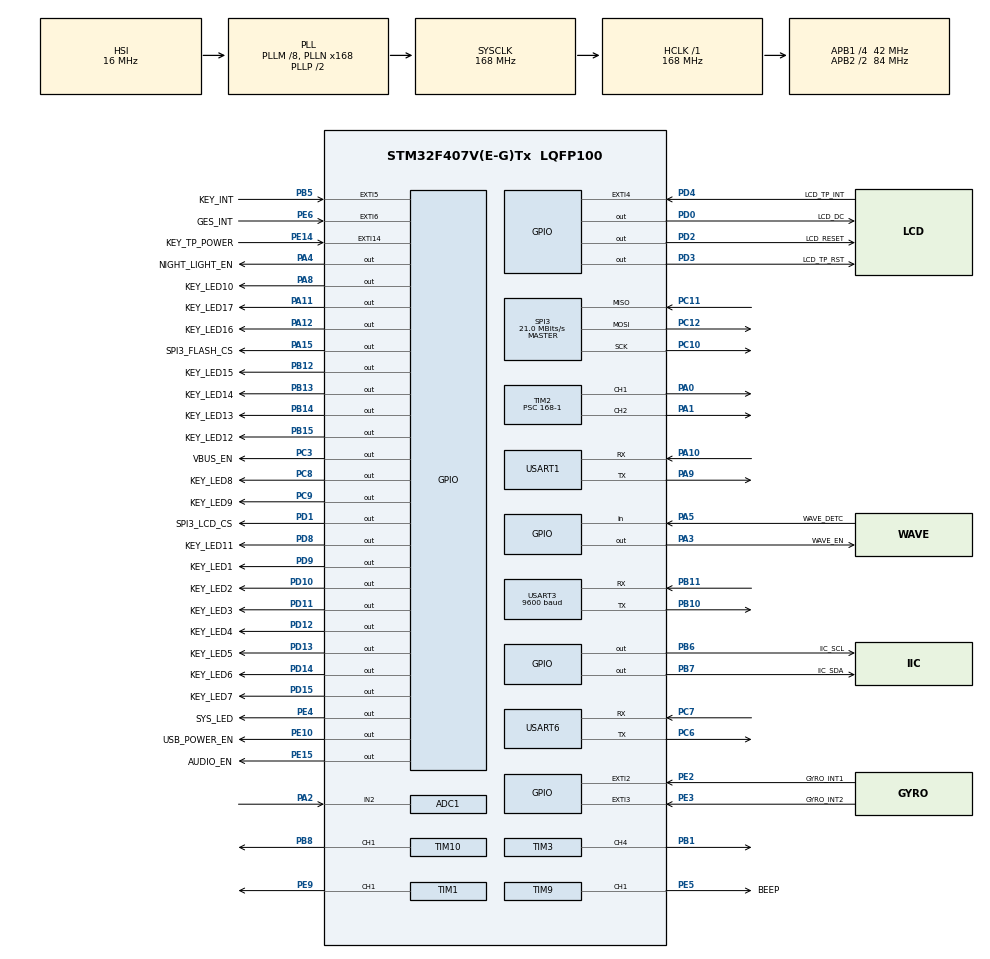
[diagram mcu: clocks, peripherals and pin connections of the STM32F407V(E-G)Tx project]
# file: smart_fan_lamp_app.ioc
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ADC1.Channel-1\#ChannelRegularConversion=ADC_CHANNEL_2
ADC1.NbrOfConversionFlag=1
ADC1.Rank-1\#ChannelRegularConversion=1
ADC1.SamplingTime-1\#ChannelRegularConversion=ADC_SAMPLETIME_3CYCLES
ADC1.master=1
Dma.Request0=USART1_RX
Dma.Request1=USART1_TX
Dma.Request2=USART6_RX
Dma.Request3=USART6_TX
Dma.Request4=USART3_RX
Dma.Request5=USART3_TX
Dma.USART1_RX.0.Direction=DMA_PERIPH_TO_MEMORY
Dma.USART1_RX.0.FIFOMode=DMA_FIFOMODE_DISABLE
Dma.USART1_RX.0.Instance=DMA2_Stream2
Dma.USART1_RX.0.MemDataAlignment=DMA_MDATAALIGN_BYTE
Dma.USART1_RX.0.MemInc=DMA_MINC_ENABLE
Dma.USART1_RX.0.Mode=DMA_NORMAL
Dma.USART1_RX.0.PeriphDataAlignment=DMA_PDATAALIGN_BYTE
Dma.USART1_RX.0.PeriphInc=DMA_PINC_DISABLE
Dma.USART1_RX.0.Priority=DMA_PRIORITY_LOW
Dma.USART1_TX.1.Direction=DMA_MEMORY_TO_PERIPH
Dma.USART1_TX.1.FIFOMode=DMA_FIFOMODE_DISABLE
Dma.USART1_TX.1.Instance=DMA2_Stream7
Dma.USART1_TX.1.MemDataAlignment=DMA_MDATAALIGN_BYTE
Dma.USART1_TX.1.MemInc=DMA_MINC_ENABLE
Dma.USART1_TX.1.Mode=DMA_NORMAL
Dma.USART1_TX.1.PeriphDataAlignment=DMA_PDATAALIGN_BYTE
Dma.USART1_TX.1.PeriphInc=DMA_PINC_DISABLE
Dma.USART1_TX.1.Priority=DMA_PRIORITY_LOW
Dma.USART3_RX.4.Direction=DMA_PERIPH_TO_MEMORY
Dma.USART3_RX.4.FIFOMode=DMA_FIFOMODE_DISABLE
Dma.USART3_RX.4.Instance=DMA1_Stream1
Dma.USART3_RX.4.MemDataAlignment=DMA_MDATAALIGN_BYTE
Dma.USART3_RX.4.MemInc=DMA_MINC_ENABLE
Dma.USART3_RX.4.Mode=DMA_NORMAL
Dma.USART3_RX.4.PeriphDataAlignment=DMA_PDATAALIGN_BYTE
Dma.USART3_RX.4.PeriphInc=DMA_PINC_DISABLE
Dma.USART3_RX.4.Priority=DMA_PRIORITY_LOW
Dma.USART3_TX.5.Direction=DMA_MEMORY_TO_PERIPH
Dma.USART3_TX.5.FIFOMode=DMA_FIFOMODE_DISABLE
Dma.USART3_TX.5.Instance=DMA1_Stream3
Dma.USART3_TX.5.MemDataAlignment=DMA_MDATAALIGN_BYTE
Dma.USART3_TX.5.MemInc=DMA_MINC_ENABLE
Dma.USART3_TX.5.Mode=DMA_NORMAL
Dma.USART3_TX.5.PeriphDataAlignment=DMA_PDATAALIGN_BYTE
Dma.USART3_TX.5.PeriphInc=DMA_PINC_DISABLE
Dma.USART3_TX.5.Priority=DMA_PRIORITY_LOW
Dma.USART6_RX.2.Direction=DMA_PERIPH_TO_MEMORY
Dma.USART6_RX.2.FIFOMode=DMA_FIFOMODE_DISABLE
Dma.USART6_RX.2.Instance=DMA2_Stream1
Dma.USART6_RX.2.MemDataAlignment=DMA_MDATAALIGN_BYTE
Dma.USART6_RX.2.MemInc=DMA_MINC_ENABLE
Dma.USART6_RX.2.Mode=DMA_NORMAL
Dma.USART6_RX.2.PeriphDataAlignment=DMA_PDATAALIGN_BYTE
Dma.USART6_RX.2.PeriphInc=DMA_PINC_DISABLE
Dma.USART6_RX.2.Priority=DMA_PRIORITY_LOW
Dma.USART6_TX.3.Direction=DMA_MEMORY_TO_PERIPH
Dma.USART6_TX.3.FIFOMode=DMA_FIFOMODE_DISABLE
Dma.USART6_TX.3.Instance=DMA2_Stream6
Dma.USART6_TX.3.MemDataAlignment=DMA_MDATAALIGN_BYTE
Dma.USART6_TX.3.MemInc=DMA_MINC_ENABLE
Dma.USART6_TX.3.Mode=DMA_NORMAL
Dma.USART6_TX.3.PeriphDataAlignment=DMA_PDATAALIGN_BYTE
Dma.USART6_TX.3.PeriphInc=DMA_PINC_DISABLE
Dma.USART6_TX.3.Priority=DMA_PRIORITY_LOW
FREERTOS.Tasks01=defaultTask,24,128,StartDefaultTask,Default,NULL,Dynamic,NULL,NULL
Mcu.Family=STM32F4
Mcu.Name=STM32F407V(E-G)Tx
Mcu.Package=LQFP100
NVIC.DMA1_Stream1_IRQn=true\:5\:0\:false\:false\:true\:true\:false\:true\:true
NVIC.DMA1_Stream3_IRQn=true\:5\:0\:false\:false\:true\:true\:false\:true\:true
NVIC.DMA2_Stream1_IRQn=true\:5\:0\:false\:false\:true\:true\:false\:true\:true
NVIC.DMA2_Stream2_IRQn=true\:5\:0\:false\:false\:true\:true\:false\:true\:true
NVIC.DMA2_Stream6_IRQn=true\:5\:0\:false\:false\:true\:true\:false\:true\:true
NVIC.DMA2_Stream7_IRQn=true\:5\:0\:false\:false\:true\:true\:false\:true\:true
NVIC.EXTI2_IRQn=true\:5\:0\:false\:false\:true\:true\:true\:true\:true
NVIC.EXTI3_IRQn=true\:5\:0\:false\:false\:true\:true\:true\:true\:true
NVIC.EXTI4_IRQn=true\:5\:0\:false\:false\:true\:true\:true\:true\:true
NVIC.EXTI9_5_IRQn=true\:5\:0\:false\:false\:true\:true\:true\:true\:true
NVIC.PriorityGroup=NVIC_PRIORITYGROUP_4
NVIC.TIM7_IRQn=true\:0\:0\:true\:false\:true\:false\:false\:true\:true
NVIC.TimeBase=TIM7_IRQn
NVIC.TimeBaseIP=TIM7
NVIC.USART1_IRQn=true\:5\:0\:false\:false\:true\:true\:false\:true\:true
NVIC.USART3_IRQn=true\:5\:0\:false\:false\:true\:true\:true\:true\:true
NVIC.USART6_IRQn=true\:5\:0\:false\:false\:true\:true\:true\:true\:true
PA0-WKUP.Signal=S_TIM2_CH1_ETR
PA1.Signal=S_TIM2_CH2
PA10.Mode=Asynchronous
PA10.Signal=USART1_RX
PA11.GPIO_Label=KEY_LED17
PA11.GPIO_Speed=GPIO_SPEED_FREQ_VERY_HIGH
PA11.PinState=GPIO_PIN_SET
PA11.Signal=GPIO_Output
PA12.GPIO_Label=KEY_LED16
PA12.GPIO_Speed=GPIO_SPEED_FREQ_VERY_HIGH
PA12.PinState=GPIO_PIN_SET
PA12.Signal=GPIO_Output
PA13.Mode=Serial_Wire
PA13.Signal=SYS_JTMS-SWDIO
PA14.Mode=Serial_Wire
PA14.Signal=SYS_JTCK-SWCLK
PA15.GPIO_Label=SPI3_FLASH_CS
PA15.GPIO_Speed=GPIO_SPEED_FREQ_HIGH
PA15.PinState=GPIO_PIN_SET
PA15.Signal=GPIO_Output
PA2.Signal=ADCx_IN2
PA3.GPIO_Label=WAVE_EN
PA3.GPIO_Speed=GPIO_SPEED_FREQ_VERY_HIGH
PA3.PinState=GPIO_PIN_SET
PA3.Signal=GPIO_Output
PA4.GPIO_Label=NIGHT_LIGHT_EN
PA4.GPIO_Speed=GPIO_SPEED_FREQ_VERY_HIGH
PA4.PinState=GPIO_PIN_RESET
PA4.Signal=GPIO_Output
PA5.GPIO_Label=WAVE_DETC
PA5.Signal=GPIO_Input
PA8.GPIO_Label=KEY_LED10
PA8.GPIO_Speed=GPIO_SPEED_FREQ_VERY_HIGH
PA8.PinState=GPIO_PIN_SET
PA8.Signal=GPIO_Output
PA9.Mode=Asynchronous
PA9.Signal=USART1_TX
PB1.Signal=S_TIM3_CH4
PB10.Mode=Asynchronous
PB10.Signal=USART3_TX
PB11.Mode=Asynchronous
PB11.Signal=USART3_RX
PB12.GPIO_Label=KEY_LED15
PB12.GPIO_Speed=GPIO_SPEED_FREQ_VERY_HIGH
PB12.PinState=GPIO_PIN_SET
PB12.Signal=GPIO_Output
PB13.GPIO_Label=KEY_LED14
PB13.GPIO_Speed=GPIO_SPEED_FREQ_VERY_HIGH
PB13.PinState=GPIO_PIN_SET
PB13.Signal=GPIO_Output
PB14.GPIO_Label=KEY_LED13
PB14.GPIO_Speed=GPIO_SPEED_FREQ_VERY_HIGH
PB14.PinState=GPIO_PIN_SET
PB14.Signal=GPIO_Output
PB15.GPIO_Label=KEY_LED12
PB15.GPIO_Speed=GPIO_SPEED_FREQ_VERY_HIGH
PB15.PinState=GPIO_PIN_SET
PB15.Signal=GPIO_Output
PB5.GPIO_Label=KEY_INT
PB5.GPIO_ModeDefaultEXTI=GPIO_MODE_IT_RISING_FALLING
PB5.GPIO_PuPd=GPIO_PULLUP
PB5.Signal=GPXTI5
PB6.GPIO_Label=IIC_SCL
PB6.GPIO_ModeDefaultOutputPP=GPIO_MODE_OUTPUT_OD
PB6.GPIO_PuPd=GPIO_PULLUP
PB6.GPIO_Speed=GPIO_SPEED_FREQ_VERY_HIGH
PB6.PinState=GPIO_PIN_SET
PB6.Signal=GPIO_Output
PB7.GPIO_Label=IIC_SDA
PB7.GPIO_ModeDefaultOutputPP=GPIO_MODE_OUTPUT_OD
PB7.GPIO_PuPd=GPIO_PULLUP
PB7.GPIO_Speed=GPIO_SPEED_FREQ_VERY_HIGH
PB7.PinState=GPIO_PIN_SET
PB7.Signal=GPIO_Output
PB8.Signal=S_TIM10_CH1
PC10.Mode=Full_Duplex_Master
PC10.Signal=SPI3_SCK
PC11.Mode=Full_Duplex_Master
PC11.Signal=SPI3_MISO
PC12.Mode=Full_Duplex_Master
PC12.Signal=SPI3_MOSI
PC3.GPIO_Label=VBUS_EN
PC3.GPIO_Speed=GPIO_SPEED_FREQ_HIGH
PC3.Signal=GPIO_Output
PC6.Mode=Asynchronous
PC6.Signal=USART6_TX
PC7.Mode=Asynchronous
PC7.Signal=USART6_RX
PC8.GPIO_Label=KEY_LED8
PC8.GPIO_Speed=GPIO_SPEED_FREQ_VERY_HIGH
PC8.PinState=GPIO_PIN_SET
PC8.Signal=GPIO_Output
PC9.GPIO_Label=KEY_LED9
PC9.GPIO_Speed=GPIO_SPEED_FREQ_VERY_HIGH
PC9.PinState=GPIO_PIN_SET
PC9.Signal=GPIO_Output
PD0.GPIO_Label=LCD_DC
PD0.GPIO_Speed=GPIO_SPEED_FREQ_VERY_HIGH
PD0.PinState=GPIO_PIN_RESET
PD0.Signal=GPIO_Output
PD1.GPIO_Label=SPI3_LCD_CS
PD1.Signal=GPIO_Output
PD10.GPIO_Label=KEY_LED2
PD10.GPIO_Speed=GPIO_SPEED_FREQ_VERY_HIGH
PD10.PinState=GPIO_PIN_SET
PD10.Signal=GPIO_Output
PD11.GPIO_Label=KEY_LED3
PD11.GPIO_Speed=GPIO_SPEED_FREQ_VERY_HIGH
PD11.PinState=GPIO_PIN_SET
PD11.Signal=GPIO_Output
PD12.GPIO_Label=KEY_LED4
PD12.GPIO_Speed=GPIO_SPEED_FREQ_VERY_HIGH
PD12.PinState=GPIO_PIN_SET
PD12.Signal=GPIO_Output
PD13.GPIO_Label=KEY_LED5
PD13.GPIO_Speed=GPIO_SPEED_FREQ_VERY_HIGH
PD13.PinState=GPIO_PIN_SET
PD13.Signal=GPIO_Output
PD14.GPIO_Label=KEY_LED6
PD14.GPIO_Speed=GPIO_SPEED_FREQ_VERY_HIGH
PD14.PinState=GPIO_PIN_SET
PD14.Signal=GPIO_Output
PD15.GPIO_Label=KEY_LED7
PD15.GPIO_Speed=GPIO_SPEED_FREQ_VERY_HIGH
PD15.PinState=GPIO_PIN_SET
PD15.Signal=GPIO_Output
PD2.GPIO_Label=LCD_RESET
PD2.Signal=GPIO_Output
PD3.GPIO_Label=LCD_TP_RST
PD3.GPIO_Speed=GPIO_SPEED_FREQ_VERY_HIGH
PD3.PinState=GPIO_PIN_SET
PD3.Signal=GPIO_Output
PD4.GPIO_Label=LCD_TP_INT
PD4.GPIO_ModeDefaultEXTI=GPIO_MODE_IT_RISING
PD4.GPIO_PuPd=GPIO_PULLUP
PD4.Signal=GPXTI4
PD8.GPIO_Label=KEY_LED11
PD8.GPIO_Speed=GPIO_SPEED_FREQ_VERY_HIGH
PD8.PinState=GPIO_PIN_SET
PD8.Signal=GPIO_Output
PD9.GPIO_Label=KEY_LED1
PD9.GPIO_Speed=GPIO_SPEED_FREQ_VERY_HIGH
PD9.PinState=GPIO_PIN_SET
PD9.Signal=GPIO_Output
PE10.GPIO_Label=USB_POWER_EN
PE10.Signal=GPIO_Output
PE14.GPIO_Label=KEY_TP_POWER
PE14.Signal=GPXTI14
PE15.GPIO_Label=AUDIO_EN
PE15.Signal=GPIO_Output
PE2.GPIO_Label=GYRO_INT1
PE2.GPIO_ModeDefaultEXTI=GPIO_MODE_IT_RISING
PE2.Signal=GPXTI2
PE3.GPIO_Label=GYRO_INT2
PE3.Signal=GPXTI3
PE4.GPIO_Label=SYS_LED
PE4.GPIO_Speed=GPIO_SPEED_FREQ_HIGH
PE4.PinState=GPIO_PIN_SET
PE4.Signal=GPIO_Output
PE5.GPIO_Label=BEEP
PE5.Signal=S_TIM9_CH1
PE6.GPIO_Label=GES_INT
PE6.Signal=GPXTI6
PE9.Signal=S_TIM1_CH1
PH0-OSC_IN.Mode=HSE-External-Oscillator
PH0-OSC_IN.Signal=RCC_OSC_IN
PH1-OSC_OUT.Mode=HSE-External-Oscillator
PH1-OSC_OUT.Signal=RCC_OSC_OUT
ProjectManager.HeapSize=0x200
ProjectManager.StackSize=0x400
ProjectManager.TargetToolchain=MDK-ARM V5.32
RCC.48MHZClocksFreq_Value=84000000
RCC.AHBFreq_Value=168000000
RCC.APB1CLKDivider=RCC_HCLK_DIV4
RCC.APB1Freq_Value=42000000
RCC.APB1TimFreq_Value=84000000
RCC.APB2CLKDivider=RCC_HCLK_DIV2
RCC.APB2Freq_Value=84000000
RCC.APB2TimFreq_Value=168000000
RCC.CortexFreq_Value=168000000
RCC.HCLKFreq_Value=168000000
RCC.HSE_VALUE=25000000
RCC.HSI_VALUE=16000000
RCC.LSE_VALUE=32768
RCC.PLLM=8
RCC.PLLN=168
RCC.SYSCLKFreq_VALUE=168000000
RCC.SYSCLKSource=RCC_SYSCLKSOURCE_PLLCLK
RCC.VCOOutputFreq_Value=336000000
SH.ADCx_IN2.0=ADC1_IN2,IN2
SH.S_TIM10_CH1.0=TIM10_CH1,PWM Generation1 CH1
SH.S_TIM1_CH1.0=TIM1_CH1,PWM Generation1 CH1
SH.S_TIM2_CH1_ETR.0=TIM2_CH1,PWM Generation1 CH1
SH.S_TIM2_CH2.0=TIM2_CH2,PWM Generation2 CH2
SH.S_TIM3_CH4.0=TIM3_CH4,PWM Generation4 CH4
SH.S_TIM9_CH1.0=TIM9_CH1,PWM Generation1 CH1
SPI3.BaudRatePrescaler=SPI_BAUDRATEPRESCALER_2
SPI3.CLKPhase=SPI_PHASE_2EDGE
SPI3.CLKPolarity=SPI_POLARITY_HIGH
SPI3.CalculateBaudRate=21.0 MBits/s
SPI3.Direction=SPI_DIRECTION_2LINES
SPI3.Mode=SPI_MODE_MASTER
SPI3.VirtualType=VM_MASTER
TIM1.Channel-PWM\ Generation1\ CH1=TIM_CHANNEL_1
TIM1.Period=100-1
TIM1.Prescaler=72-1
TIM10.Channel=TIM_CHANNEL_1
TIM10.Period=100-1
TIM10.Prescaler=72-1
TIM2.Channel-PWM\ Generation1\ CH1=TIM_CHANNEL_1
TIM2.Channel-PWM\ Generation2\ CH2=TIM_CHANNEL_2
TIM2.Period=100-1
TIM2.Prescaler=168-1
TIM3.Channel-PWM\ Generation4\ CH4=TIM_CHANNEL_4
TIM3.Period=100-1
TIM3.Prescaler=42-1
TIM9.Channel-PWM\ Generation1\ CH1=TIM_CHANNEL_1
USART1.VirtualMode=VM_ASYNC
USART3.BaudRate=9600
USART3.VirtualMode=VM_ASYNC
USART6.VirtualMode=VM_ASYNC
VP_FREERTOS_VS_CMSIS_V2.Mode=CMSIS_V2
VP_IWDG_VS_IWDG.Mode=IWDG_Activate
VP_SYS_VS_tim7.Mode=TIM7
VP_TIM10_VS_ClockSourceINT.Mode=Enable_Timer
board=custom

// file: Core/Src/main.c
/* USER CODE BEGIN Header */
/**
  ******************************************************************************
  * @file           : main.c
  * @brief          : Main program body
  ******************************************************************************
  * @attention
  *
  * Copyright (c) 2024 STMicroelectronics.
  * All rights reserved.
  *
  * This software is licensed under terms that can be found in the LICENSE file
  * in the root directory of this software component.
  * If no LICENSE file comes with this software, it is provided AS-IS.
  *
  ******************************************************************************
  */
/* USER CODE END Header */
#include "main.h"
#include "cmsis_os.h"
#include "adc.h"
#include "dma.h"
#include "iwdg.h"
#include "spi.h"
#include "tim.h"
#include "usart.h"
#include "gpio.h"

void SystemClock_Config(void);
void MX_FREERTOS_Init(void);

int main(void)
{

  /* MCU Configuration--------------------------------------------------------*/

  /* Reset of all peripherals, Initializes the Flash interface and the Systick. */
  HAL_Init();

  /* Configure the system clock */
  SystemClock_Config();

  /* Initialize all configured peripherals */
  MX_GPIO_Init();
  MX_DMA_Init();
  MX_USART1_UART_Init();
  MX_IWDG_Init();
  MX_SPI3_Init();
  MX_TIM2_Init();
  MX_ADC1_Init();
  MX_TIM1_Init();
  MX_TIM3_Init();
  MX_TIM9_Init();
  MX_USART3_UART_Init();
  MX_USART6_UART_Init();
  MX_TIM10_Init();

  /* Init scheduler */
  osKernelInitialize();

  /* Call init function for freertos objects (in cmsis_os2.c) */
  MX_FREERTOS_Init();

  /* Start scheduler */
  osKernelStart();

  /* We should never get here as control is now taken by the scheduler */

  /* Infinite loop */
  while (1)
  {

  }
}

void SystemClock_Config(void)
{
  RCC_OscInitTypeDef RCC_OscInitStruct = {0};
  RCC_ClkInitTypeDef RCC_ClkInitStruct = {0};

  /** Configure the main internal regulator output voltage
  */
  __HAL_RCC_PWR_CLK_ENABLE();
  __HAL_PWR_VOLTAGESCALING_CONFIG(PWR_REGULATOR_VOLTAGE_SCALE1);

  /** Initializes the RCC Oscillators according to the specified parameters
  * in the RCC_OscInitTypeDef structure.
  */
  RCC_OscInitStruct.OscillatorType = RCC_OSCILLATORTYPE_HSI|RCC_OSCILLATORTYPE_LSI;
  RCC_OscInitStruct.HSIState = RCC_HSI_ON;
  RCC_OscInitStruct.HSICalibrationValue = RCC_HSICALIBRATION_DEFAULT;
  RCC_OscInitStruct.LSIState = RCC_LSI_ON;
  RCC_OscInitStruct.PLL.PLLState = RCC_PLL_ON;
  RCC_OscInitStruct.PLL.PLLSource = RCC_PLLSOURCE_HSI;
  RCC_OscInitStruct.PLL.PLLM = 8;
  RCC_OscInitStruct.PLL.PLLN = 168;
  RCC_OscInitStruct.PLL.PLLP = RCC_PLLP_DIV2;
  RCC_OscInitStruct.PLL.PLLQ = 4;
  if (HAL_RCC_OscConfig(&RCC_OscInitStruct) != HAL_OK)
  {
    Error_Handler();
  }

  /** Initializes the CPU, AHB and APB buses clocks
  */
  RCC_ClkInitStruct.ClockType = RCC_CLOCKTYPE_HCLK|RCC_CLOCKTYPE_SYSCLK
                              |RCC_CLOCKTYPE_PCLK1|RCC_CLOCKTYPE_PCLK2;
  RCC_ClkInitStruct.SYSCLKSource = RCC_SYSCLKSOURCE_PLLCLK;
  RCC_ClkInitStruct.AHBCLKDivider = RCC_SYSCLK_DIV1;
  RCC_ClkInitStruct.APB1CLKDivider = RCC_HCLK_DIV4;
  RCC_ClkInitStruct.APB2CLKDivider = RCC_HCLK_DIV2;

  if (HAL_RCC_ClockConfig(&RCC_ClkInitStruct, FLASH_LATENCY_5) != HAL_OK)
  {
    Error_Handler();
  }
}

void HAL_TIM_PeriodElapsedCallback(TIM_HandleTypeDef *htim)
{
  if (htim->Instance == TIM7) {
    HAL_IncTick();
  }
}

void Error_Handler(void)
{
  __disable_irq();
  while (1)
  {
  }
}

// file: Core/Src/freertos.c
/* USER CODE BEGIN Header */
/**
  ******************************************************************************
  * File Name          : freertos.c
  * Description        : Code for freertos applications
  ******************************************************************************
  * @attention
  *
  * Copyright (c) 2024 STMicroelectronics.
  * All rights reserved.
  *
  * This software is licensed under terms that can be found in the LICENSE file
  * in the root directory of this software component.
  * If no LICENSE file comes with this software, it is provided AS-IS.
  *
  ******************************************************************************
  */
/* USER CODE END Header */

#include "FreeRTOS.h"
#include "task.h"
#include "main.h"
#include "cmsis_os.h"

/* USER CODE BEGIN Includes */
#include "app/app.h"
/* USER CODE END Includes */

/* Definitions for defaultTask */
osThreadId_t defaultTaskHandle;
const osThreadAttr_t defaultTask_attributes = {
  .name = "defaultTask",
  .stack_size = 128 * 4,
  .priority = (osPriority_t) osPriorityNormal,
};

void StartDefaultTask(void *argument);

void MX_FREERTOS_Init(void); /* (MISRA C 2004 rule 8.1) */

void MX_FREERTOS_Init(void) {

  /* Create the thread(s) */
  /* creation of defaultTask */
  defaultTaskHandle = osThreadNew(StartDefaultTask, NULL, &defaultTask_attributes);

}

void StartDefaultTask(void *argument)
{
  /* USER CODE BEGIN StartDefaultTask */
  app_init();

  /* Infinite loop */
  for(;;)
  {
    osDelay(1);
  }
  /* USER CODE END StartDefaultTask */
}
